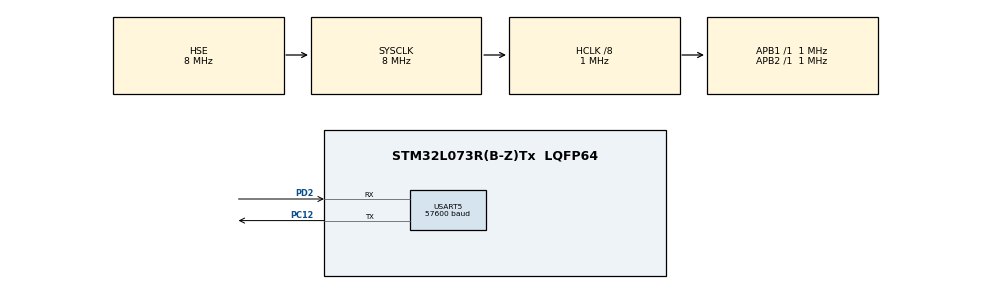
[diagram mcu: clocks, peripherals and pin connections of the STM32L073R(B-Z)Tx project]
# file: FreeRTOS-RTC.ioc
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FREERTOS.Tasks01=defaultTask,0,128,StartDefaultTask,Default,NULL,Dynamic,NULL,NULL
FREERTOS.configTOTAL_HEAP_SIZE=10240
Mcu.Family=STM32L0
Mcu.Name=STM32L073R(B-Z)Tx
Mcu.Package=LQFP64
NVIC.RTC_IRQn=true\:3\:0\:false\:false\:true\:true\:true\:true
NVIC.USART4_5_IRQn=true\:3\:0\:false\:false\:true\:true\:true\:true
PA13.Mode=Serial_Wire
PA13.Signal=SYS_SWDIO
PA14.Mode=Serial_Wire
PA14.Signal=SYS_SWCLK
PC12.Mode=Asynchronous
PC12.Signal=USART5_TX
PC14-OSC32_IN.Mode=LSE-External-Oscillator
PC14-OSC32_IN.Signal=RCC_OSC32_IN
PC15-OSC32_OUT.Mode=LSE-External-Oscillator
PC15-OSC32_OUT.Signal=RCC_OSC32_OUT
PD2.Mode=Asynchronous
PD2.Signal=USART5_RX
PH0-OSC_IN.Mode=HSE-External-Oscillator
PH0-OSC_IN.Signal=RCC_OSC_IN
PH1-OSC_OUT.Mode=HSE-External-Oscillator
PH1-OSC_OUT.Signal=RCC_OSC_OUT
ProjectManager.HeapSize=0x200
ProjectManager.StackSize=0x400
ProjectManager.TargetToolchain=MDK-ARM V5
RCC.AHBCLKDivider=RCC_SYSCLK_DIV8
RCC.AHBFreq_Value=1000000
RCC.APB1Freq_Value=1000000
RCC.APB1TimFreq_Value=1000000
RCC.APB2Freq_Value=1000000
RCC.APB2TimFreq_Value=1000000
RCC.HCLKFreq_Value=1000000
RCC.HSE_VALUE=8000000
RCC.HSI16_VALUE=16000000
RCC.HSI48_VALUE=48000000
RCC.HSI_VALUE=16000000
RCC.LptimClockSelection=RCC_LPTIM1CLKSOURCE_LSE
RCC.MSI_VALUE=2097000
RCC.RTCClockSelection=RCC_RTCCLKSOURCE_LSE
RCC.RTCClockSelectionVirtual=RCC_RTCCLKSOURCE_LSE
RCC.SYSCLKFreq_VALUE=8000000
RCC.SYSCLKSource=RCC_SYSCLKSOURCE_HSE
RCC.VCOOutputFreq_Value=48000000
RTC.Date=1
RTC.Format=RTC_FORMAT_BIN
RTC.Hours=12
RTC.Minutes=30
RTC.Month=RTC_MONTH_MAY
RTC.Seconds=30
RTC.WakeUpClock-WakeUp=RTC_WAKEUPCLOCK_CK_SPRE_16BITS
RTC.WakeUpCounter-WakeUp=4
RTC.WeekDay=RTC_WEEKDAY_FRIDAY
RTC.Year=20
USART5.BaudRate=57600
USART5.VirtualMode-Asynchronous=VM_ASYNC
VP_FREERTOS_VS_CMSIS_V1.Mode=CMSIS_V1
VP_RTC_VS_RTC_Activate.Mode=RTC_Enabled
VP_RTC_VS_RTC_Calendar.Mode=RTC_Calendar
VP_RTC_VS_RTC_WakeUp_intern.Mode=WakeUp
board=custom

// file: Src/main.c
/* USER CODE BEGIN Header */
/**
  ******************************************************************************
  * @file           : main.c
  * @brief          : Main program body
  ******************************************************************************
  * @attention
  *
  * <h2><center>&copy; Copyright (c) 2020 STMicroelectronics.
  * All rights reserved.</center></h2>
  *
  * This software component is licensed by ST under BSD 3-Clause license,
  * the "License"; You may not use this file except in compliance with the
  * License. You may obtain a copy of the License at:
  *                        opensource.org/licenses/BSD-3-Clause
  *
  ******************************************************************************
  */
/* USER CODE END Header */

#include "main.h"
#include "cmsis_os.h"
#include "rtc.h"
#include "usart.h"
#include "gpio.h"

void SystemClock_Config(void);
void MX_FREERTOS_Init(void);

int main(void)
{

  /* MCU Configuration--------------------------------------------------------*/

  /* Reset of all peripherals, Initializes the Flash interface and the Systick. */
  HAL_Init();

  /* Configure the system clock */
  SystemClock_Config();

  /* Initialize all configured peripherals */
  MX_GPIO_Init();
  MX_RTC_Init();
  MX_USART5_UART_Init();

  /* Call init function for freertos objects (in freertos.c) */
  MX_FREERTOS_Init();
  /* Start scheduler */
  osKernelStart();

  /* We should never get here as control is now taken by the scheduler */
  /* Infinite loop */
  while (1)
  {

  }
}

void SystemClock_Config(void)
{
  RCC_OscInitTypeDef RCC_OscInitStruct = {0};
  RCC_ClkInitTypeDef RCC_ClkInitStruct = {0};
  RCC_PeriphCLKInitTypeDef PeriphClkInit = {0};

  /** Configure the main internal regulator output voltage
  */
  __HAL_PWR_VOLTAGESCALING_CONFIG(PWR_REGULATOR_VOLTAGE_SCALE1);
  /** Configure LSE Drive Capability
  */
  HAL_PWR_EnableBkUpAccess();
  __HAL_RCC_LSEDRIVE_CONFIG(RCC_LSEDRIVE_LOW);
  /** Initializes the CPU, AHB and APB busses clocks
  */
  RCC_OscInitStruct.OscillatorType = RCC_OSCILLATORTYPE_HSE|RCC_OSCILLATORTYPE_LSE;
  RCC_OscInitStruct.HSEState = RCC_HSE_ON;
  RCC_OscInitStruct.LSEState = RCC_LSE_ON;
  RCC_OscInitStruct.PLL.PLLState = RCC_PLL_NONE;
  if (HAL_RCC_OscConfig(&RCC_OscInitStruct) != HAL_OK)
  {
    Error_Handler();
  }
  /** Initializes the CPU, AHB and APB busses clocks
  */
  RCC_ClkInitStruct.ClockType = RCC_CLOCKTYPE_HCLK|RCC_CLOCKTYPE_SYSCLK
                              |RCC_CLOCKTYPE_PCLK1|RCC_CLOCKTYPE_PCLK2;
  RCC_ClkInitStruct.SYSCLKSource = RCC_SYSCLKSOURCE_HSE;
  RCC_ClkInitStruct.AHBCLKDivider = RCC_SYSCLK_DIV8;
  RCC_ClkInitStruct.APB1CLKDivider = RCC_HCLK_DIV1;
  RCC_ClkInitStruct.APB2CLKDivider = RCC_HCLK_DIV1;

  if (HAL_RCC_ClockConfig(&RCC_ClkInitStruct, FLASH_LATENCY_0) != HAL_OK)
  {
    Error_Handler();
  }
  PeriphClkInit.PeriphClockSelection = RCC_PERIPHCLK_RTC;
  PeriphClkInit.RTCClockSelection = RCC_RTCCLKSOURCE_LSE;
  if (HAL_RCCEx_PeriphCLKConfig(&PeriphClkInit) != HAL_OK)
  {
    Error_Handler();
  }
}

void Error_Handler(void)
{
}

/************************ (C) COPYRIGHT STMicroelectronics *****END OF FILE****/

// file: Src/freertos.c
/* USER CODE BEGIN Header */
/**
  ******************************************************************************
  * File Name          : freertos.c
  * Description        : Code for freertos applications
  ******************************************************************************
  * @attention
  *
  * <h2><center>&copy; Copyright (c) 2020 STMicroelectronics.
  * All rights reserved.</center></h2>
  *
  * This software component is licensed by ST under Ultimate Liberty license
  * SLA0044, the "License"; You may not use this file except in compliance with
  * the License. You may obtain a copy of the License at:
  *                             www.st.com/SLA0044
  *
  ******************************************************************************
  */
/* USER CODE END Header */

#include "FreeRTOS.h"
#include "task.h"
#include "main.h"
#include "cmsis_os.h"

/* USER CODE BEGIN Includes */
#include "queue.h"
#include "usart.h"
#include "rs232.h"
#include "rtc.h"
/* USER CODE END Includes */

/* USER CODE BEGIN Variables */
QueueHandle_t QueueRS232Tx;
/* USER CODE END Variables */
osThreadId defaultTaskHandle;

void StartDefaultTask(void const * argument);

void MX_FREERTOS_Init(void); /* (MISRA C 2004 rule 8.1) */

/* GetIdleTaskMemory prototype (linked to static allocation support) */
void vApplicationGetIdleTaskMemory( StaticTask_t **ppxIdleTaskTCBBuffer, StackType_t **ppxIdleTaskStackBuffer, uint32_t *pulIdleTaskStackSize );

/* USER CODE BEGIN GET_IDLE_TASK_MEMORY */
static StaticTask_t xIdleTaskTCBBuffer;
static StackType_t xIdleStack[configMINIMAL_STACK_SIZE];

void vApplicationGetIdleTaskMemory( StaticTask_t **ppxIdleTaskTCBBuffer, StackType_t **ppxIdleTaskStackBuffer, uint32_t *pulIdleTaskStackSize )
{
  *ppxIdleTaskTCBBuffer = &xIdleTaskTCBBuffer;
  *ppxIdleTaskStackBuffer = &xIdleStack[0];
  *pulIdleTaskStackSize = configMINIMAL_STACK_SIZE;
  /* place for user code */
}
/* USER CODE END GET_IDLE_TASK_MEMORY */

void MX_FREERTOS_Init(void) {
  /* USER CODE BEGIN Init */
     memset(USARTData, 0, NoUSART_MAX*sizeof(ST_USART_Data));
  /* USER CODE END Init */

  /* USER CODE BEGIN RTOS_QUEUES */
  /* add queues, ... */
	QueueRS232Tx = xQueueCreate(USART5_QUEUE_COUNT, USART_BUFF_SIZE);
  /* USER CODE END RTOS_QUEUES */

  /* Create the thread(s) */
  /* definition and creation of defaultTask */
  osThreadDef(defaultTask, StartDefaultTask, osPriorityNormal, 0, 128);
  defaultTaskHandle = osThreadCreate(osThread(defaultTask), NULL);

}

void StartDefaultTask(void const * argument)
{
  for(;;)
  {
    osDelay(1);
  }
}

/************************ (C) COPYRIGHT STMicroelectronics *****END OF FILE****/
